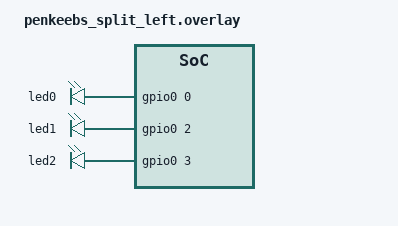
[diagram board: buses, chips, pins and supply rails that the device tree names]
#include "penkeebs_split.dtsi"

&default_transform {
    col-offset = <0>;
};

/ {
    aliases {
        led-red = &led0;
        led-green = &led1;
        led-blue = &led2;
    };

    leds {
        compatible = "gpio-leds";
        status = "okay";
        led0: led_0 {
            gpios = <&gpio0 0 GPIO_ACTIVE_HIGH>;
        };
        led1: led_1 {
            gpios = <&gpio0 2 GPIO_ACTIVE_HIGH>;
        }    
        led2: led_2 {
            gpios = <&gpio0 3 GPIO_ACTIVE_HIGH>;
        };
    };
};
